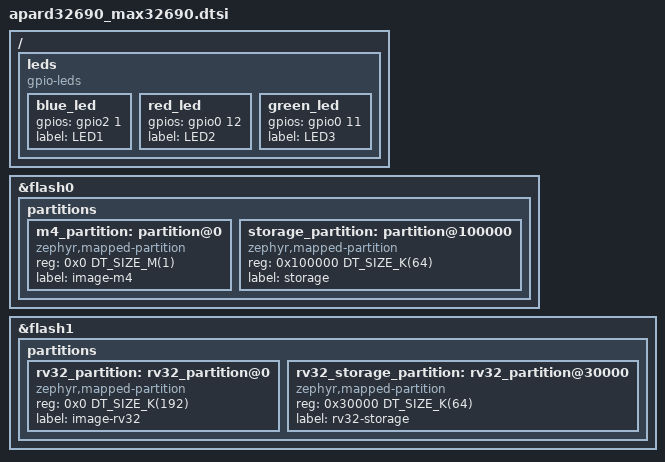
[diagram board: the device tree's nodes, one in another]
/*
 * Copyright (c) 2026 Analog Devices, Inc.
 *
 * SPDX-License-Identifier: Apache-2.0
 */

/ {
	leds {
		compatible = "gpio-leds";

		blue_led: blue_led {
			gpios = <&gpio2 1 GPIO_ACTIVE_HIGH>;
			label = "LED1";
		};

		red_led: red_led {
			gpios = <&gpio0 12 GPIO_ACTIVE_HIGH>;
			label = "LED2";
		};

		green_led: green_led {
			gpios = <&gpio0 11 GPIO_ACTIVE_HIGH>;
			label = "LED3";
		};
	};
};

&flash0 {
	partitions {
		ranges;
		#address-cells = <1>;
		#size-cells = <1>;

		m4_partition: partition@0 {
			compatible = "zephyr,mapped-partition";
			reg = <0x0 DT_SIZE_M(1)>;
			label = "image-m4";
		};

		storage_partition: partition@100000 {
			compatible = "zephyr,mapped-partition";
			reg = <0x100000 DT_SIZE_K(64)>;
			label = "storage";
		};
	};
};

&flash1 {
	partitions {
		ranges;
		#address-cells = <1>;
		#size-cells = <1>;

		rv32_partition: rv32_partition@0 {
			compatible = "zephyr,mapped-partition";
			reg = <0x0 DT_SIZE_K(192)>;
			label = "image-rv32";
		};

		rv32_storage_partition: rv32_partition@30000 {
			compatible = "zephyr,mapped-partition";
			reg = <0x30000 DT_SIZE_K(64)>;
			label = "rv32-storage";
		};
	};
};
